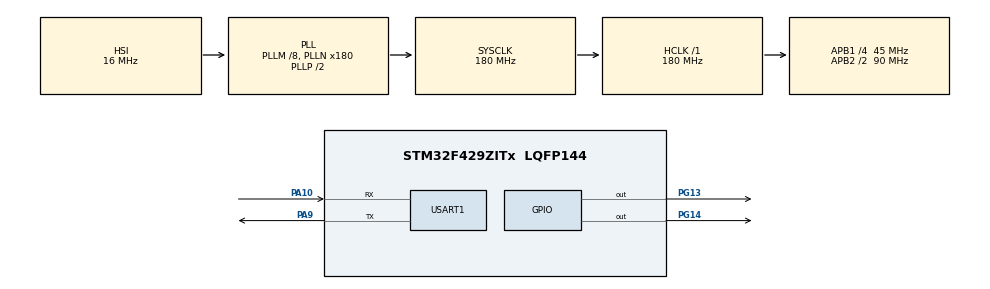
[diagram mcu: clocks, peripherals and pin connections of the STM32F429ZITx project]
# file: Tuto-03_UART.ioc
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Dma.Request0=USART1_RX
Dma.USART1_RX.0.Direction=DMA_PERIPH_TO_MEMORY
Dma.USART1_RX.0.FIFOMode=DMA_FIFOMODE_DISABLE
Dma.USART1_RX.0.Instance=DMA2_Stream2
Dma.USART1_RX.0.MemDataAlignment=DMA_MDATAALIGN_BYTE
Dma.USART1_RX.0.MemInc=DMA_MINC_ENABLE
Dma.USART1_RX.0.Mode=DMA_CIRCULAR
Dma.USART1_RX.0.PeriphDataAlignment=DMA_PDATAALIGN_BYTE
Dma.USART1_RX.0.PeriphInc=DMA_PINC_DISABLE
Dma.USART1_RX.0.Priority=DMA_PRIORITY_LOW
Mcu.Family=STM32F4
Mcu.Name=STM32F429ZITx
Mcu.Package=LQFP144
NVIC.DMA2_Stream2_IRQn=true\:0\:0\:false\:false\:true\:false\:true
NVIC.PriorityGroup=NVIC_PRIORITYGROUP_4
NVIC.TIM8_TRG_COM_TIM14_IRQn=true\:0\:0\:false\:false\:true\:true\:true
NVIC.USART1_IRQn=true\:0\:0\:false\:false\:true\:true\:true
PA10.Mode=Asynchronous
PA10.Signal=USART1_RX
PA9.Mode=Asynchronous
PA9.Signal=USART1_TX
PG13.Signal=GPIO_Output
PG14.Signal=GPIO_Output
PH0/OSC_IN.Mode=HSE-External-Oscillator
PH0/OSC_IN.Signal=RCC_OSC_IN
PH1/OSC_OUT.Mode=HSE-External-Oscillator
PH1/OSC_OUT.Signal=RCC_OSC_OUT
ProjectManager.HeapSize=0x200
ProjectManager.StackSize=0x400
ProjectManager.TargetToolchain=STM32CubeIDE
RCC.48MHZClocksFreq_Value=90000000
RCC.AHBFreq_Value=180000000
RCC.APB1CLKDivider=RCC_HCLK_DIV4
RCC.APB1Freq_Value=45000000
RCC.APB1TimFreq_Value=90000000
RCC.APB2CLKDivider=RCC_HCLK_DIV2
RCC.APB2Freq_Value=90000000
RCC.APB2TimFreq_Value=180000000
RCC.CortexFreq_Value=180000000
RCC.HCLKFreq_Value=180000000
RCC.HSE_VALUE=8000000
RCC.HSI_VALUE=16000000
RCC.LSE_VALUE=32768
RCC.PLLM=8
RCC.PLLN=180
RCC.SYSCLKFreq_VALUE=180000000
RCC.SYSCLKSource=RCC_SYSCLKSOURCE_PLLCLK
RCC.VCOOutputFreq_Value=360000000
TIM14.AutoReloadPreload=TIM_AUTORELOAD_PRELOAD_ENABLE
TIM14.Channel=TIM_CHANNEL_1
TIM14.ClockDivision=TIM_CLOCKDIVISION_DIV1
TIM14.Period=500-1
TIM14.Prescaler=9000-1
USART1.VirtualMode=VM_ASYNC
VP_TIM14_VS_ClockSourceINT.Mode=Enable_Timer
VP_TIM14_VS_no_output1.Mode=Output Compare1 No Output
board=custom

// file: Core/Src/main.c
/* USER CODE BEGIN Header */
/**
  ******************************************************************************
  * @file           : main.c
  * @brief          : Main program body
  ******************************************************************************
  * @attention
  *
  * <h2><center>&copy; Copyright (c) 2021 STMicroelectronics.
  * All rights reserved.</center></h2>
  *
  * This software component is licensed by ST under BSD 3-Clause license,
  * the "License"; You may not use this file except in compliance with the
  * License. You may obtain a copy of the License at:
  *                        opensource.org/licenses/BSD-3-Clause
  *
  ******************************************************************************
  */
/* USER CODE END Header */
#include "main.h"
#include "dma.h"
#include "tim.h"
#include "usart.h"
#include "gpio.h"

/* USER CODE BEGIN Includes */
#include "blinking.h"
#include "uart.h"
/* USER CODE END Includes */

void SystemClock_Config(void);

int main(void)
{

  /* MCU Configuration--------------------------------------------------------*/

  /* Reset of all peripherals, Initializes the Flash interface and the Systick. */
  HAL_Init();

  /* Configure the system clock */
  SystemClock_Config();

  /* Initialize all configured peripherals */
  MX_GPIO_Init();
  MX_DMA_Init();
  MX_USART1_UART_Init();
  MX_TIM14_Init();
  /* USER CODE BEGIN 2 */

  led_Init();
  uartInit();

  /* USER CODE END 2 */

  /* Infinite loop */
  /* USER CODE BEGIN WHILE */
  uint8_t count;
  while (1)
  {
    if (uartAvailable() > 0)
    {
      uint8_t rx_data;

      rx_data = uartRead();
      uartPrintf("Uart Rx : %c\n\r", rx_data);
    }

    /* USER CODE END WHILE */

  }
}

void SystemClock_Config(void)
{
  RCC_OscInitTypeDef RCC_OscInitStruct = {0};
  RCC_ClkInitTypeDef RCC_ClkInitStruct = {0};

  /** Configure the main internal regulator output voltage
  */
  __HAL_RCC_PWR_CLK_ENABLE();
  __HAL_PWR_VOLTAGESCALING_CONFIG(PWR_REGULATOR_VOLTAGE_SCALE1);
  /** Initializes the RCC Oscillators according to the specified parameters
  * in the RCC_OscInitTypeDef structure.
  */
  RCC_OscInitStruct.OscillatorType = RCC_OSCILLATORTYPE_HSI;
  RCC_OscInitStruct.HSIState = RCC_HSI_ON;
  RCC_OscInitStruct.HSICalibrationValue = RCC_HSICALIBRATION_DEFAULT;
  RCC_OscInitStruct.PLL.PLLState = RCC_PLL_ON;
  RCC_OscInitStruct.PLL.PLLSource = RCC_PLLSOURCE_HSI;
  RCC_OscInitStruct.PLL.PLLM = 8;
  RCC_OscInitStruct.PLL.PLLN = 180;
  RCC_OscInitStruct.PLL.PLLP = RCC_PLLP_DIV2;
  RCC_OscInitStruct.PLL.PLLQ = 4;
  if (HAL_RCC_OscConfig(&RCC_OscInitStruct) != HAL_OK)
  {
    Error_Handler();
  }
  /** Activate the Over-Drive mode
  */
  if (HAL_PWREx_EnableOverDrive() != HAL_OK)
  {
    Error_Handler();
  }
  /** Initializes the CPU, AHB and APB buses clocks
  */
  RCC_ClkInitStruct.ClockType = RCC_CLOCKTYPE_HCLK|RCC_CLOCKTYPE_SYSCLK
                              |RCC_CLOCKTYPE_PCLK1|RCC_CLOCKTYPE_PCLK2;
  RCC_ClkInitStruct.SYSCLKSource = RCC_SYSCLKSOURCE_PLLCLK;
  RCC_ClkInitStruct.AHBCLKDivider = RCC_SYSCLK_DIV1;
  RCC_ClkInitStruct.APB1CLKDivider = RCC_HCLK_DIV4;
  RCC_ClkInitStruct.APB2CLKDivider = RCC_HCLK_DIV2;

  if (HAL_RCC_ClockConfig(&RCC_ClkInitStruct, FLASH_LATENCY_5) != HAL_OK)
  {
    Error_Handler();
  }
}

void Error_Handler(void)
{
  __disable_irq();
  while (1)
  {
  }
}

/************************ (C) COPYRIGHT STMicroelectronics *****END OF FILE****/
